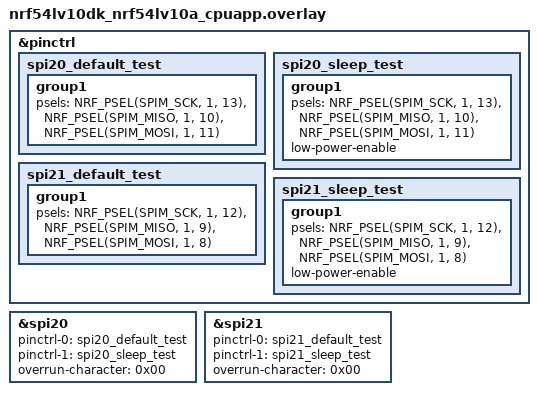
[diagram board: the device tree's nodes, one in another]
/*
 * Copyright (c) 2025 Nordic Semiconductor ASA
 *
 * SPDX-License-Identifier: LicenseRef-Nordic-5-Clause
 */

&pinctrl {
	spi20_default_test: spi20_default_test {
		group1 {
			psels = <NRF_PSEL(SPIM_SCK, 1, 13)>,
				<NRF_PSEL(SPIM_MISO, 1, 10)>,
				<NRF_PSEL(SPIM_MOSI, 1, 11)>;
		};
	};

	spi20_sleep_test: spi20_sleep_test {
		group1 {
			psels = <NRF_PSEL(SPIM_SCK, 1, 13)>,
				<NRF_PSEL(SPIM_MISO, 1, 10)>,
				<NRF_PSEL(SPIM_MOSI, 1, 11)>;
			low-power-enable;
		};
	};

	spi21_default_test: spi21_default_test {
		group1 {
			psels = <NRF_PSEL(SPIM_SCK, 1, 12)>,
				<NRF_PSEL(SPIM_MISO, 1, 9)>,
				<NRF_PSEL(SPIM_MOSI, 1, 8)>;
		};
	};

	spi21_sleep_test: spi21_sleep_test {
		group1 {
			psels = <NRF_PSEL(SPIM_SCK, 1, 12)>,
				<NRF_PSEL(SPIM_MISO, 1, 9)>,
				<NRF_PSEL(SPIM_MOSI, 1, 8)>;
			low-power-enable;
		};
	};
};

&spi20 {
	status = "okay";
	pinctrl-0 = <&spi20_default_test>;
	pinctrl-1 = <&spi20_sleep_test>;
	pinctrl-names = "default", "sleep";
	overrun-character = <0x00>;
};

&spi21 {
	status = "okay";
	pinctrl-0 = <&spi21_default_test>;
	pinctrl-1 = <&spi21_sleep_test>;
	pinctrl-names = "default", "sleep";
	overrun-character = <0x00>;
};

/* spi30 inaccessible due to console on uart30 */
